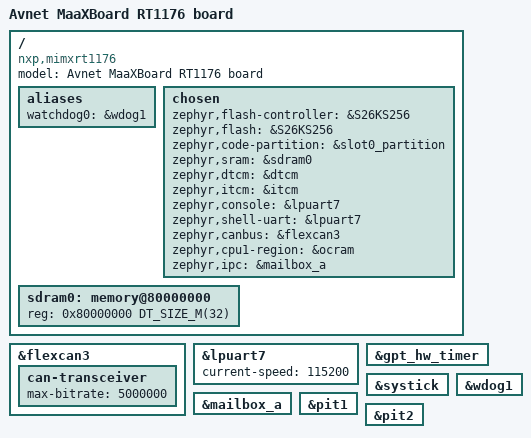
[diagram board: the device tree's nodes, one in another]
/*
 * Copyright 2021-2022,2024 NXP
 * Copyright 2024 Avnet
 *
 * SPDX-License-Identifier: Apache-2.0
 */

/dts-v1/;

#include <nxp/nxp_rt11xx_cm7.dtsi>
#include "maax_imxrt1176.dtsi"

/ {
	model = "Avnet MaaXBoard RT1176 board";
	compatible = "nxp,mimxrt1176";

	aliases {
		watchdog0 = &wdog1;
	};

chosen {
    zephyr,flash-controller = &S26KS256;
    zephyr,flash = &S26KS256;
    zephyr,code-partition = &slot0_partition;
    zephyr,sram = &sdram0;
    zephyr,dtcm = &dtcm;
    zephyr,itcm = &itcm;
    zephyr,console = &lpuart7;
    zephyr,shell-uart = &lpuart7;
    zephyr,canbus = &flexcan3;
    zephyr,cpu1-region = &ocram;
    zephyr,ipc = &mailbox_a;
};

	sdram0: memory@80000000 {
		device_type = "memory";
		reg = <0x80000000 DT_SIZE_M(32)>;
	};
};

&flexcan3 {
	status = "okay";
	can-transceiver {
		max-bitrate = <5000000>;
	};
};

&lpuart7 {
	status = "okay";
	current-speed = <115200>;
};

/* GPT and Systick are both enabled. If power management is enabled, GPT
 * will be used instead of systick as it allows the core clock to be gated.
 */
&gpt_hw_timer {
	status = "okay";
};

&systick {
	status = "okay";
};

&wdog1 {
	status = "okay";
};

&mailbox_a {
	status = "okay";
};

&pit1 {
	status = "okay";
};

&pit2 {
	status = "okay";
};
